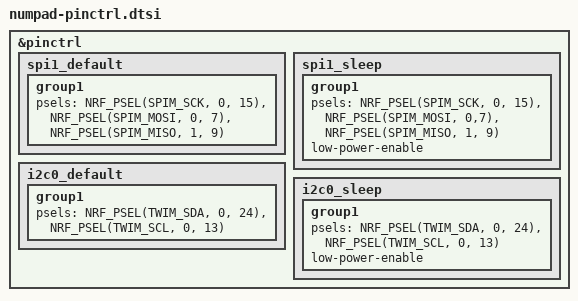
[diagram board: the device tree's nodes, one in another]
/*
 * Copyright (c) 2022 The ZMK Contributors
 * SPDX-License-Identifier: MIT
 */

&pinctrl {
    /*
    pwm1_default: pwm1_default {
        group1 {
            psels = <NRF_PSEL(PWM_OUT0, 0, 24)>;
        };
    };
    pwm1_sleep: pwm1_sleep {
        group1 {
            psels = <NRF_PSEL(PWM_OUT0, 0, 24)>;
            low-power-enable;    
       };
    };
    */
    spi1_default: spi1_default {
        group1 {
            psels = <NRF_PSEL(SPIM_SCK, 0, 15)>,
                <NRF_PSEL(SPIM_MOSI, 0, 7)>,
                <NRF_PSEL(SPIM_MISO, 1, 9)>;
        };
    };
    spi1_sleep: spi1_sleep {
        group1 {
            psels = <NRF_PSEL(SPIM_SCK, 0, 15)>,
                <NRF_PSEL(SPIM_MOSI, 0,7)>,
                <NRF_PSEL(SPIM_MISO, 1, 9)>;
            low-power-enable;
        };
    };

    i2c0_default: i2c0_default {
        group1 {
            psels = <NRF_PSEL(TWIM_SDA, 0, 24)>,
                    <NRF_PSEL(TWIM_SCL, 0, 13)>;
        };
    };

    i2c0_sleep: i2c0_sleep {
        group1 {
            psels = <NRF_PSEL(TWIM_SDA, 0, 24)>,
                    <NRF_PSEL(TWIM_SCL, 0, 13)>;
            low-power-enable;
        };
    };

};



